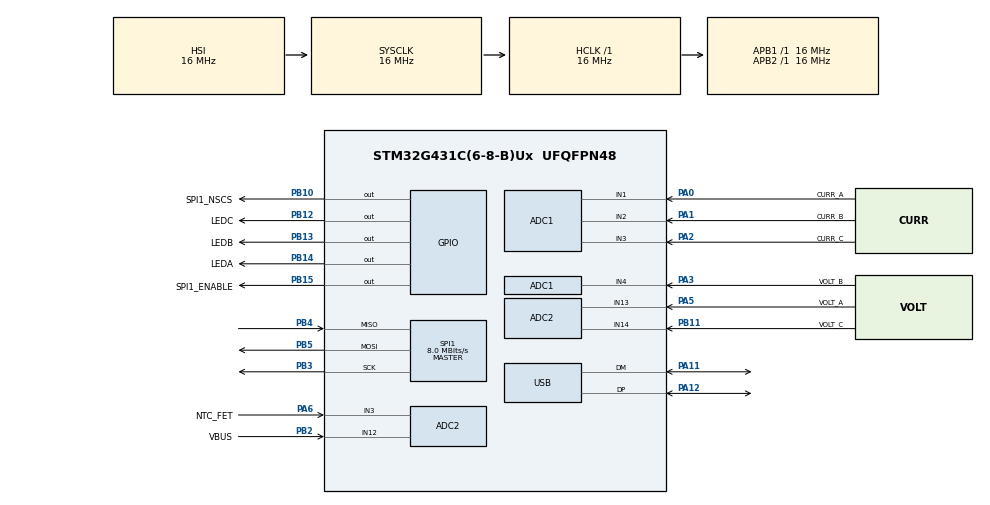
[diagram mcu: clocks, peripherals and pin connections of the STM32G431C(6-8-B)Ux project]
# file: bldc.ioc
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ADC1.Channel-0\#ChannelRegularConversion=ADC_CHANNEL_1
ADC1.NbrOfConversionFlag=1
ADC1.OffsetNumber-0\#ChannelRegularConversion=ADC_OFFSET_NONE
ADC1.Rank-0\#ChannelRegularConversion=1
ADC1.SamplingTime-0\#ChannelRegularConversion=ADC_SAMPLETIME_2CYCLES_5
ADC1.master=1
ADC2.Channel-2\#ChannelRegularConversion=ADC_CHANNEL_3
ADC2.ContinuousConvMode=ENABLE
ADC2.NbrOfConversionFlag=1
ADC2.OffsetNumber-2\#ChannelRegularConversion=ADC_OFFSET_NONE
ADC2.Rank-2\#ChannelRegularConversion=1
ADC2.SamplingTime-2\#ChannelRegularConversion=ADC_SAMPLETIME_2CYCLES_5
Mcu.Family=STM32G4
Mcu.Name=STM32G431C(6-8-B)Ux
Mcu.Package=UFQFPN48
NVIC.PriorityGroup=NVIC_PRIORITYGROUP_4
NVIC.USB_LP_IRQn=true\:0\:0\:false\:false\:true\:false\:true\:true
PA0.GPIO_Label=CURR_A
PA0.Mode=IN1-Single-Ended
PA0.Signal=ADC1_IN1
PA1.GPIO_Label=CURR_B
PA1.Mode=IN2-Single-Ended
PA1.Signal=ADC1_IN2
PA11.Mode=Device
PA11.Signal=USB_DM
PA12.Mode=Device
PA12.Signal=USB_DP
PA13.Mode=Serial_Wire
PA13.Signal=SYS_JTMS-SWDIO
PA14.Mode=Serial_Wire
PA14.Signal=SYS_JTCK-SWCLK
PA2.GPIO_Label=CURR_C
PA2.Mode=IN3-Single-Ended
PA2.Signal=ADC1_IN3
PA3.GPIO_Label=VOLT_B
PA3.Mode=IN4-Single-Ended
PA3.Signal=ADC1_IN4
PA5.GPIO_Label=VOLT_A
PA5.Mode=IN13-Single-Ended
PA5.Signal=ADC2_IN13
PA6.GPIO_Label=NTC_FET
PA6.Mode=IN3-Single-Ended
PA6.Signal=ADC2_IN3
PB10.GPIO_Label=SPI1_NSCS
PB10.PinState=GPIO_PIN_SET
PB10.Signal=GPIO_Output
PB11.GPIO_Label=VOLT_C
PB11.Mode=IN14-Single-Ended
PB11.Signal=ADC2_IN14
PB12.GPIO_Label=LEDC
PB12.Signal=GPIO_Output
PB13.GPIO_Label=LEDB
PB13.Signal=GPIO_Output
PB14.GPIO_Label=LEDA
PB14.Signal=GPIO_Output
PB15.GPIO_Label=SPI1_ENABLE
PB15.Signal=GPIO_Output
PB2.GPIO_Label=VBUS
PB2.Mode=IN12-Single-Ended
PB2.Signal=ADC2_IN12
PB3.Mode=Full_Duplex_Master
PB3.Signal=SPI1_SCK
PB4.Mode=Full_Duplex_Master
PB4.Signal=SPI1_MISO
PB5.Mode=Full_Duplex_Master
PB5.Signal=SPI1_MOSI
PF0-OSC_IN.Mode=HSE-External-Oscillator
PF0-OSC_IN.Signal=RCC_OSC_IN
PF1-OSC_OUT.Mode=HSE-External-Oscillator
PF1-OSC_OUT.Signal=RCC_OSC_OUT
ProjectManager.HeapSize=0x200
ProjectManager.StackSize=0x400
ProjectManager.TargetToolchain=CMake
RCC.AHBFreq_Value=16000000
RCC.APB1Freq_Value=16000000
RCC.APB1TimFreq_Value=16000000
RCC.APB2Freq_Value=16000000
RCC.APB2TimFreq_Value=16000000
RCC.CortexFreq_Value=16000000
RCC.EXTERNAL_CLOCK_VALUE=12288000
RCC.HCLKFreq_Value=16000000
RCC.HSE_VALUE=8000000
RCC.HSI48_VALUE=48000000
RCC.HSI_VALUE=16000000
RCC.LSE_VALUE=32768
RCC.PLLN=12
RCC.PLLSourceVirtual=RCC_PLLSOURCE_HSE
RCC.SYSCLKFreq_VALUE=16000000
RCC.USBFreq_Value=48000000
RCC.VCOOutputFreq_Value=96000000
SPI1.CLKPhase=SPI_PHASE_2EDGE
SPI1.CalculateBaudRate=8.0 MBits/s
SPI1.DataSize=SPI_DATASIZE_16BIT
SPI1.Direction=SPI_DIRECTION_2LINES
SPI1.Mode=SPI_MODE_MASTER
SPI1.VirtualType=VM_MASTER
USB_DEVICE.CLASS_NAME_FS=CDC
USB_DEVICE.VirtualMode=Cdc
USB_DEVICE.VirtualModeFS=Cdc_FS
VP_SYS_VS_DBSignals.Mode=DisableDeadBatterySignals
VP_USB_DEVICE_VS_USB_DEVICE_CDC_FS.Mode=CDC_FS
board=custom

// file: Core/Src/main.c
/* USER CODE BEGIN Header */
/**
  ******************************************************************************
  * @file           : main.c
  * @brief          : Main program body
  ******************************************************************************
  * @attention
  *
  * Copyright (c) 2026 STMicroelectronics.
  * All rights reserved.
  *
  * This software is licensed under terms that can be found in the LICENSE file
  * in the root directory of this software component.
  * If no LICENSE file comes with this software, it is provided AS-IS.
  *
  ******************************************************************************
  */
/* USER CODE END Header */
#include "main.h"
#include "usb_device.h"

/* USER CODE BEGIN Includes */

#include "telemetry.h"

/* USER CODE END Includes */

ADC_HandleTypeDef hadc1;
ADC_HandleTypeDef hadc2;

SPI_HandleTypeDef hspi1;

void SystemClock_Config(void);
static void MX_GPIO_Init(void);
static void MX_ADC2_Init(void);
static void MX_ADC1_Init(void);
static void MX_SPI1_Init(void);

int main(void)
{

  /* MCU Configuration--------------------------------------------------------*/

  /* Reset of all peripherals, Initializes the Flash interface and the Systick. */
  HAL_Init();

  /* Configure the system clock */
  SystemClock_Config();

  /* Initialize all configured peripherals */
  MX_GPIO_Init();
  MX_USB_Device_Init();
  MX_ADC2_Init();
  MX_ADC1_Init();
  MX_SPI1_Init();
  /* USER CODE BEGIN 2 */
  Telemetry_Init();

  /* USER CODE END 2 */

  /* Infinite loop */
  while (1)
  {

    /* USER CODE BEGIN 3 */
    Telemetry_Task(HAL_GetTick());
  }
  /* USER CODE END 3 */
}

void SystemClock_Config(void)
{
  RCC_OscInitTypeDef RCC_OscInitStruct = {0};
  RCC_ClkInitTypeDef RCC_ClkInitStruct = {0};

  /** Configure the main internal regulator output voltage
  */
  HAL_PWREx_ControlVoltageScaling(PWR_REGULATOR_VOLTAGE_SCALE1);

  /** Initializes the RCC Oscillators according to the specified parameters
  * in the RCC_OscInitTypeDef structure.
  */
  RCC_OscInitStruct.OscillatorType = RCC_OSCILLATORTYPE_HSI|RCC_OSCILLATORTYPE_HSE;
  RCC_OscInitStruct.HSEState = RCC_HSE_ON;
  RCC_OscInitStruct.HSIState = RCC_HSI_ON;
  RCC_OscInitStruct.HSICalibrationValue = RCC_HSICALIBRATION_DEFAULT;
  RCC_OscInitStruct.PLL.PLLState = RCC_PLL_ON;
  RCC_OscInitStruct.PLL.PLLSource = RCC_PLLSOURCE_HSE;
  RCC_OscInitStruct.PLL.PLLM = RCC_PLLM_DIV1;
  RCC_OscInitStruct.PLL.PLLN = 12;
  RCC_OscInitStruct.PLL.PLLP = RCC_PLLP_DIV2;
  RCC_OscInitStruct.PLL.PLLQ = RCC_PLLQ_DIV2;
  RCC_OscInitStruct.PLL.PLLR = RCC_PLLR_DIV2;
  if (HAL_RCC_OscConfig(&RCC_OscInitStruct) != HAL_OK)
  {
    Error_Handler();
  }

  /** Initializes the CPU, AHB and APB buses clocks
  */
  RCC_ClkInitStruct.ClockType = RCC_CLOCKTYPE_HCLK|RCC_CLOCKTYPE_SYSCLK
                              |RCC_CLOCKTYPE_PCLK1|RCC_CLOCKTYPE_PCLK2;
  RCC_ClkInitStruct.SYSCLKSource = RCC_SYSCLKSOURCE_HSI;
  RCC_ClkInitStruct.AHBCLKDivider = RCC_SYSCLK_DIV1;
  RCC_ClkInitStruct.APB1CLKDivider = RCC_HCLK_DIV1;
  RCC_ClkInitStruct.APB2CLKDivider = RCC_HCLK_DIV1;

  if (HAL_RCC_ClockConfig(&RCC_ClkInitStruct, FLASH_LATENCY_0) != HAL_OK)
  {
    Error_Handler();
  }
}

static void MX_ADC1_Init(void)
{

  ADC_MultiModeTypeDef multimode = {0};
  ADC_ChannelConfTypeDef sConfig = {0};

  /** Common config
  */
  hadc1.Instance = ADC1;
  hadc1.Init.ClockPrescaler = ADC_CLOCK_SYNC_PCLK_DIV2;
  hadc1.Init.Resolution = ADC_RESOLUTION_12B;
  hadc1.Init.DataAlign = ADC_DATAALIGN_RIGHT;
  hadc1.Init.GainCompensation = 0;
  hadc1.Init.ScanConvMode = ADC_SCAN_DISABLE;
  hadc1.Init.EOCSelection = ADC_EOC_SINGLE_CONV;
  hadc1.Init.LowPowerAutoWait = DISABLE;
  hadc1.Init.ContinuousConvMode = DISABLE;
  hadc1.Init.NbrOfConversion = 1;
  hadc1.Init.DiscontinuousConvMode = DISABLE;
  hadc1.Init.ExternalTrigConv = ADC_SOFTWARE_START;
  hadc1.Init.ExternalTrigConvEdge = ADC_EXTERNALTRIGCONVEDGE_NONE;
  hadc1.Init.DMAContinuousRequests = DISABLE;
  hadc1.Init.Overrun = ADC_OVR_DATA_PRESERVED;
  hadc1.Init.OversamplingMode = DISABLE;
  if (HAL_ADC_Init(&hadc1) != HAL_OK)
  {
    Error_Handler();
  }

  /** Configure the ADC multi-mode
  */
  multimode.Mode = ADC_MODE_INDEPENDENT;
  if (HAL_ADCEx_MultiModeConfigChannel(&hadc1, &multimode) != HAL_OK)
  {
    Error_Handler();
  }

  /** Configure Regular Channel
  */
  sConfig.Channel = ADC_CHANNEL_1;
  sConfig.Rank = ADC_REGULAR_RANK_1;
  sConfig.SamplingTime = ADC_SAMPLETIME_2CYCLES_5;
  sConfig.SingleDiff = ADC_SINGLE_ENDED;
  sConfig.OffsetNumber = ADC_OFFSET_NONE;
  sConfig.Offset = 0;
  if (HAL_ADC_ConfigChannel(&hadc1, &sConfig) != HAL_OK)
  {
    Error_Handler();
  }

}

static void MX_ADC2_Init(void)
{

  ADC_ChannelConfTypeDef sConfig = {0};

  /** Common config
  */
  hadc2.Instance = ADC2;
  hadc2.Init.ClockPrescaler = ADC_CLOCK_SYNC_PCLK_DIV2;
  hadc2.Init.Resolution = ADC_RESOLUTION_12B;
  hadc2.Init.DataAlign = ADC_DATAALIGN_RIGHT;
  hadc2.Init.GainCompensation = 0;
  hadc2.Init.ScanConvMode = ADC_SCAN_DISABLE;
  hadc2.Init.EOCSelection = ADC_EOC_SINGLE_CONV;
  hadc2.Init.LowPowerAutoWait = DISABLE;
  hadc2.Init.ContinuousConvMode = ENABLE;
  hadc2.Init.NbrOfConversion = 1;
  hadc2.Init.DiscontinuousConvMode = DISABLE;
  hadc2.Init.ExternalTrigConv = ADC_SOFTWARE_START;
  hadc2.Init.ExternalTrigConvEdge = ADC_EXTERNALTRIGCONVEDGE_NONE;
  hadc2.Init.DMAContinuousRequests = DISABLE;
  hadc2.Init.Overrun = ADC_OVR_DATA_PRESERVED;
  hadc2.Init.OversamplingMode = DISABLE;
  if (HAL_ADC_Init(&hadc2) != HAL_OK)
  {
    Error_Handler();
  }

  /** Configure Regular Channel
  */
  sConfig.Channel = ADC_CHANNEL_3;
  sConfig.Rank = ADC_REGULAR_RANK_1;
  sConfig.SamplingTime = ADC_SAMPLETIME_2CYCLES_5;
  sConfig.SingleDiff = ADC_SINGLE_ENDED;
  sConfig.OffsetNumber = ADC_OFFSET_NONE;
  sConfig.Offset = 0;
  if (HAL_ADC_ConfigChannel(&hadc2, &sConfig) != HAL_OK)
  {
    Error_Handler();
  }

}

static void MX_SPI1_Init(void)
{

  /* SPI1 parameter configuration*/
  hspi1.Instance = SPI1;
  hspi1.Init.Mode = SPI_MODE_MASTER;
  hspi1.Init.Direction = SPI_DIRECTION_2LINES;
  hspi1.Init.DataSize = SPI_DATASIZE_16BIT;
  hspi1.Init.CLKPolarity = SPI_POLARITY_LOW;
  hspi1.Init.CLKPhase = SPI_PHASE_2EDGE;
  hspi1.Init.NSS = SPI_NSS_SOFT;
  hspi1.Init.BaudRatePrescaler = SPI_BAUDRATEPRESCALER_2;
  hspi1.Init.FirstBit = SPI_FIRSTBIT_MSB;
  hspi1.Init.TIMode = SPI_TIMODE_DISABLE;
  hspi1.Init.CRCCalculation = SPI_CRCCALCULATION_DISABLE;
  hspi1.Init.CRCPolynomial = 7;
  hspi1.Init.CRCLength = SPI_CRC_LENGTH_DATASIZE;
  hspi1.Init.NSSPMode = SPI_NSS_PULSE_DISABLE;
  if (HAL_SPI_Init(&hspi1) != HAL_OK)
  {
    Error_Handler();
  }

}

static void MX_GPIO_Init(void)
{
  GPIO_InitTypeDef GPIO_InitStruct = {0};

  /* GPIO Ports Clock Enable */
  __HAL_RCC_GPIOF_CLK_ENABLE();
  __HAL_RCC_GPIOA_CLK_ENABLE();
  __HAL_RCC_GPIOB_CLK_ENABLE();

  /*Configure GPIO pin Output Level */
  HAL_GPIO_WritePin(SPI1_NSCS_GPIO_Port, SPI1_NSCS_Pin, GPIO_PIN_SET);

  /*Configure GPIO pin Output Level */
  HAL_GPIO_WritePin(GPIOB, LEDC_Pin|LEDB_Pin|LEDA_Pin|SPI1_ENABLE_Pin, GPIO_PIN_RESET);

  /*Configure GPIO pins : SPI1_NSCS_Pin LEDC_Pin LEDB_Pin LEDA_Pin
                           SPI1_ENABLE_Pin */
  GPIO_InitStruct.Pin = SPI1_NSCS_Pin|LEDC_Pin|LEDB_Pin|LEDA_Pin
                          |SPI1_ENABLE_Pin;
  GPIO_InitStruct.Mode = GPIO_MODE_OUTPUT_PP;
  GPIO_InitStruct.Pull = GPIO_NOPULL;
  GPIO_InitStruct.Speed = GPIO_SPEED_FREQ_LOW;
  HAL_GPIO_Init(GPIOB, &GPIO_InitStruct);

}

void Error_Handler(void)
{
  __disable_irq();
  while (1)
  {
  }
}
